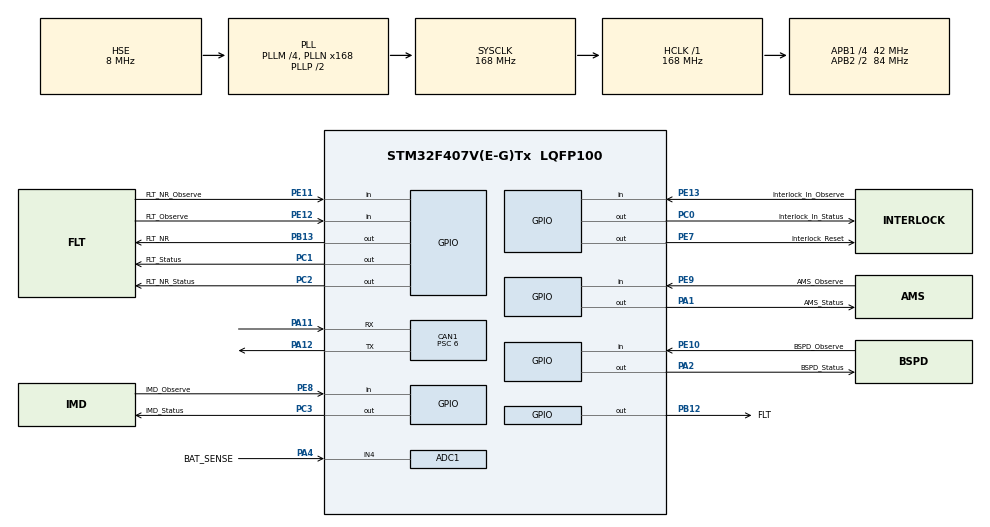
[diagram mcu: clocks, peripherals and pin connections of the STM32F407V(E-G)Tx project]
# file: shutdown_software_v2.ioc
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ADC1.Channel-0\#ChannelRegularConversion=ADC_CHANNEL_4
ADC1.ClockPrescaler=ADC_CLOCK_SYNC_PCLK_DIV4
ADC1.ContinuousConvMode=DISABLE
ADC1.DMAContinuousRequests=DISABLE
ADC1.DataAlign=ADC_DATAALIGN_RIGHT
ADC1.DiscontinuousConvMode=DISABLE
ADC1.EOCSelection=ADC_EOC_SEQ_CONV
ADC1.EnableAnalogWatchDog=false
ADC1.ExternalTrigConv=ADC_SOFTWARE_START
ADC1.ExternalTrigConvEdge=ADC_EXTERNALTRIGCONVEDGE_NONE
ADC1.InjNumberOfConversion=0
ADC1.NbrOfConversion=1
ADC1.NbrOfConversionFlag=1
ADC1.Rank-0\#ChannelRegularConversion=1
ADC1.Resolution=ADC_RESOLUTION_12B
ADC1.SamplingTime-0\#ChannelRegularConversion=ADC_SAMPLETIME_3CYCLES
ADC1.ScanConvMode=DISABLE
ADC1.master=1
CAN1.BS1=CAN_BS1_11TQ
CAN1.BS2=CAN_BS2_2TQ
CAN1.CalculateTimeBit=1500
CAN1.CalculateTimeQuantum=142.85714285714286
CAN1.Prescaler=6
CAN1.TimeSeg1=CAN_BS1_2TQ
CAN1.TimeSeg2=CAN_BS2_2TQ
Mcu.Family=STM32F4
Mcu.Name=STM32F407V(E-G)Tx
Mcu.Package=LQFP100
NVIC.PriorityGroup=NVIC_PRIORITYGROUP_4
NVIC.TIM3_IRQn=true\:0\:0\:false\:false\:true\:true
PA1.GPIO_Label=AMS_Status
PA1.Signal=GPIO_Output
PA11.Mode=Master
PA11.Signal=CAN1_RX
PA12.Mode=Master
PA12.Signal=CAN1_TX
PA13.Mode=Serial_Wire
PA13.Signal=SYS_JTMS-SWDIO
PA14.Mode=Serial_Wire
PA14.Signal=SYS_JTCK-SWCLK
PA2.GPIO_Label=BSPD_Status
PA2.Signal=GPIO_Output
PA4.GPIO_Label=BAT_SENSE
PA4.Signal=ADCx_IN4
PB12.GPIO_Label=FLT
PB12.Signal=GPIO_Output
PB13.GPIO_Label=FLT_NR
PB13.Signal=GPIO_Output
PC0.GPIO_Label=Interlock_In_Status
PC0.Signal=GPIO_Output
PC1.GPIO_Label=FLT_Status
PC1.Signal=GPIO_Output
PC2.GPIO_Label=FLT_NR_Status
PC2.Signal=GPIO_Output
PC3.GPIO_Label=IMD_Status
PC3.Signal=GPIO_Output
PE10.GPIO_Label=BSPD_Observe
PE10.Signal=GPIO_Input
PE11.GPIO_Label=FLT_NR_Observe
PE11.Signal=GPIO_Input
PE12.GPIO_Label=FLT_Observe
PE12.Signal=GPIO_Input
PE13.GPIO_Label=Interlock_In_Observe
PE13.Signal=GPIO_Input
PE7.GPIO_Label=Interlock_Reset
PE7.Signal=GPIO_Output
PE8.GPIO_Label=IMD_Observe
PE8.Signal=GPIO_Input
PE9.GPIO_Label=AMS_Observe
PE9.Signal=GPIO_Input
PH0-OSC_IN.Mode=HSE-External-Oscillator
PH0-OSC_IN.Signal=RCC_OSC_IN
PH1-OSC_OUT.Mode=HSE-External-Oscillator
PH1-OSC_OUT.Signal=RCC_OSC_OUT
ProjectManager.HeapSize=0x200
ProjectManager.StackSize=0x400
ProjectManager.TargetToolchain=TrueSTUDIO
RCC.48MHZClocksFreq_Value=84000000
RCC.AHBFreq_Value=168000000
RCC.APB1CLKDivider=RCC_HCLK_DIV4
RCC.APB1Freq_Value=42000000
RCC.APB1TimFreq_Value=84000000
RCC.APB2CLKDivider=RCC_HCLK_DIV2
RCC.APB2Freq_Value=84000000
RCC.APB2TimFreq_Value=168000000
RCC.CortexFreq_Value=168000000
RCC.HCLKFreq_Value=168000000
RCC.HSE_VALUE=8000000
RCC.HSI_VALUE=16000000
RCC.LSE_VALUE=32768
RCC.PLLM=4
RCC.PLLN=168
RCC.PLLSourceVirtual=RCC_PLLSOURCE_HSE
RCC.SYSCLKFreq_VALUE=168000000
RCC.SYSCLKSource=RCC_SYSCLKSOURCE_PLLCLK
RCC.VCOOutputFreq_Value=336000000
SH.ADCx_IN4.0=ADC1_IN4,IN4
TIM3.Period=199
TIM3.Prescaler=42000
VP_TIM3_VS_ClockSourceINT.Mode=Internal
VP_TIM3_VS_OPM.Mode=OPM_bit
board=shutdown_software_v2

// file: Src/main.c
/**
  ******************************************************************************
  * @file           : main.c
  * @brief          : Main program body
  ******************************************************************************
  ******************************************************************************
  */
#include "main.h"
#include "stm32f4xx_hal.h"
#include "adc.h"
#include "can.h"
#include "tim.h"
#include "gpio.h"

/* USER CODE BEGIN Includes */
#include "scheduler.h"
#include "Shutdown.h"
/* USER CODE END Includes */

/* USER CODE BEGIN PV */
/* Private variables ---------------------------------------------------------*/

/* USER CODE END PV */

void SystemClock_Config(void);

/* USER CODE BEGIN PFP */
/* Private function prototypes -----------------------------------------------*/

/* USER CODE END PFP */

/* USER CODE BEGIN 0 */
uint16_t adc;

// Timer callback function
void HAL_TIM_PeriodElapsedCallback(TIM_HandleTypeDef *htim)
{
	if (htim->Instance==TIM3) // Reset back high after 100ms
	{
		HAL_GPIO_WritePin(INTERLOCK_RESET_GROUP, INTERLOCK_RESET_PIN, GPIO_PIN_RESET);
	}
}

/* USER CODE END 0 */

int main(void)

{

  /* MCU Configuration----------------------------------------------------------*/

  /* Reset of all peripherals, Initializes the Flash interface and the Systick. */
  HAL_Init();

  /* Configure the system clock */
  SystemClock_Config();

  /* Initialize all configured peripherals */
  MX_GPIO_Init();
  MX_ADC1_Init();
  MX_CAN1_Init();
  MX_TIM3_Init();
  /* USER CODE BEGIN 2 */
  Init_MyCAN();
  init();
  /* USER CODE END 2 */

  /* Infinite loop */
  /* USER CODE BEGIN WHILE */
  Schedule schedule;
  MakeSchedule(&schedule, 3);
  AddTask(&schedule, &mainloop, MAIN_LOOP_FREQ);
  AddTask(&schedule, &checkCANMessages, 1);
  AddTask(&schedule, &sendHeartbeat, 700);

  while (1)
  {
	  RunSchedule(&schedule);

  /* USER CODE END WHILE */

  }

}

void SystemClock_Config(void)
{

  RCC_OscInitTypeDef RCC_OscInitStruct;
  RCC_ClkInitTypeDef RCC_ClkInitStruct;

    /**Configure the main internal regulator output voltage
    */
  __HAL_RCC_PWR_CLK_ENABLE();

  __HAL_PWR_VOLTAGESCALING_CONFIG(PWR_REGULATOR_VOLTAGE_SCALE1);

    /**Initializes the CPU, AHB and APB busses clocks
    */
  RCC_OscInitStruct.OscillatorType = RCC_OSCILLATORTYPE_HSE;
  RCC_OscInitStruct.HSEState = RCC_HSE_ON;
  RCC_OscInitStruct.PLL.PLLState = RCC_PLL_ON;
  RCC_OscInitStruct.PLL.PLLSource = RCC_PLLSOURCE_HSE;
  RCC_OscInitStruct.PLL.PLLM = 4;
  RCC_OscInitStruct.PLL.PLLN = 168;
  RCC_OscInitStruct.PLL.PLLP = RCC_PLLP_DIV2;
  RCC_OscInitStruct.PLL.PLLQ = 4;
  if (HAL_RCC_OscConfig(&RCC_OscInitStruct) != HAL_OK)
  {
    _Error_Handler(__FILE__, __LINE__);
  }

    /**Initializes the CPU, AHB and APB busses clocks
    */
  RCC_ClkInitStruct.ClockType = RCC_CLOCKTYPE_HCLK|RCC_CLOCKTYPE_SYSCLK
                              |RCC_CLOCKTYPE_PCLK1|RCC_CLOCKTYPE_PCLK2;
  RCC_ClkInitStruct.SYSCLKSource = RCC_SYSCLKSOURCE_PLLCLK;
  RCC_ClkInitStruct.AHBCLKDivider = RCC_SYSCLK_DIV1;
  RCC_ClkInitStruct.APB1CLKDivider = RCC_HCLK_DIV4;
  RCC_ClkInitStruct.APB2CLKDivider = RCC_HCLK_DIV2;

  if (HAL_RCC_ClockConfig(&RCC_ClkInitStruct, FLASH_LATENCY_5) != HAL_OK)
  {
    _Error_Handler(__FILE__, __LINE__);
  }

    /**Configure the Systick interrupt time
    */
  HAL_SYSTICK_Config(HAL_RCC_GetHCLKFreq()/1000);

    /**Configure the Systick
    */
  HAL_SYSTICK_CLKSourceConfig(SYSTICK_CLKSOURCE_HCLK);

  /* SysTick_IRQn interrupt configuration */
  HAL_NVIC_SetPriority(SysTick_IRQn, 0, 0);
}

void _Error_Handler(char *file, int line)
{
  while(1)
  {
  }
}

/************************ (C) COPYRIGHT STMicroelectronics *****END OF FILE****/
